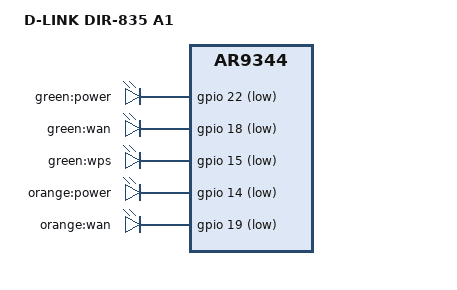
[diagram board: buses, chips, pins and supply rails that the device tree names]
// SPDX-License-Identifier: GPL-2.0-or-later OR MIT

#include "ar9344_dlink_dir-8x5.dtsi"

/ {
	model = "D-LINK DIR-835 A1";
	compatible = "dlink,dir-835-a1", "qca,ar9344";

	aliases {
		led-boot = &led_power_orange;
		led-failsafe = &led_power_orange;
		led-running = &led_power_green;
		led-upgrade = &led_power_orange;
	};

	leds {
		compatible = "gpio-leds";

		led_power_green: power_green {
			label = "green:power";
			gpios = <&gpio 22 GPIO_ACTIVE_LOW>;
		};

		wan_green {
			label = "green:wan";
			gpios = <&gpio 18 GPIO_ACTIVE_LOW>;
		};

		wps {
			label = "green:wps";
			gpios = <&gpio 15 GPIO_ACTIVE_LOW>;
		};

		led_power_orange: power_orange {
			label = "orange:power";
			gpios = <&gpio 14 GPIO_ACTIVE_LOW>;
		};

		wan_orange {
			label = "orange:wan";
			gpios = <&gpio 19 GPIO_ACTIVE_LOW>;
		};
	};
};
